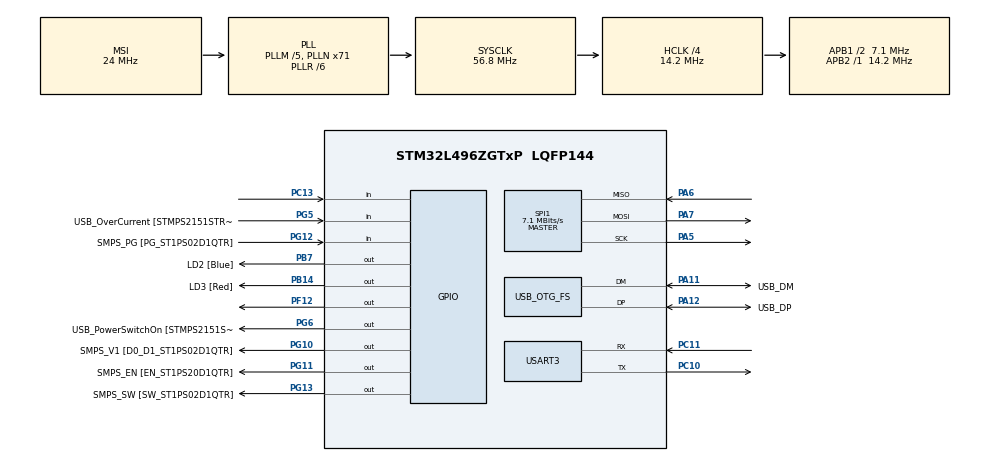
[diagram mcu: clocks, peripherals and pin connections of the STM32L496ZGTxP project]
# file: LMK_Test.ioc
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Mcu.Family=STM32L4
Mcu.Name=STM32L496ZGTxP
Mcu.Package=LQFP144
NVIC.OTG_FS_IRQn=true\:0\:0\:false\:false\:true\:true\:true\:true
NVIC.PriorityGroup=NVIC_PRIORITYGROUP_4
PA10.GPIO_Label=USB_ID
PA10.Signal=USB_OTG_FS_ID
PA11.GPIO_Label=USB_DM
PA11.Mode=Host_Only
PA11.Signal=USB_OTG_FS_DM
PA12.GPIO_Label=USB_DP
PA12.Mode=Host_Only
PA12.Signal=USB_OTG_FS_DP
PA13\ (JTMS/SWDIO).GPIO_Label=TMS
PA13\ (JTMS/SWDIO).Mode=Trace_Asynchronous_SW
PA13\ (JTMS/SWDIO).Signal=SYS_JTMS-SWDIO
PA14\ (JTCK/SWCLK).GPIO_Label=TCK
PA14\ (JTCK/SWCLK).Mode=Trace_Asynchronous_SW
PA14\ (JTCK/SWCLK).Signal=SYS_JTCK-SWCLK
PA5.Mode=Full_Duplex_Master
PA5.Signal=SPI1_SCK
PA6.Mode=Full_Duplex_Master
PA6.Signal=SPI1_MISO
PA7.Mode=Full_Duplex_Master
PA7.Signal=SPI1_MOSI
PA8.GPIO_Label=USB_SOF [TP1]
PA8.Signal=USB_OTG_FS_SOF
PA9.GPIO_Label=USB_VBUS
PA9.Signal=USB_OTG_FS_VBUS
PB14.GPIO_Label=LD3 [Red]
PB14.Signal=GPIO_Output
PB3\ (JTDO/TRACESWO).GPIO_Label=SWO
PB3\ (JTDO/TRACESWO).Mode=Trace_Asynchronous_SW
PB3\ (JTDO/TRACESWO).Signal=SYS_JTDO-SWO
PB7.GPIO_Label=LD2 [Blue]
PB7.Signal=GPIO_Output
PC10.Mode=Asynchronous
PC10.Signal=USART3_TX
PC11.Mode=Asynchronous
PC11.Signal=USART3_RX
PC13.Signal=GPIO_Input
PC14-OSC32_IN\ (PC14).Mode=LSE-External-Oscillator
PC14-OSC32_IN\ (PC14).Signal=RCC_OSC32_IN
PC15-OSC32_OUT\ (PC15).Mode=LSE-External-Oscillator
PC15-OSC32_OUT\ (PC15).Signal=RCC_OSC32_OUT
PF12.Signal=GPIO_Output
PG10.GPIO_Label=SMPS_V1 [D0_D1_ST1PS02D1QTR]
PG10.Signal=GPIO_Output
PG11.GPIO_Label=SMPS_EN [EN_ST1PS20D1QTR]
PG11.Signal=GPIO_Output
PG12.GPIO_Label=SMPS_PG [PG_ST1PS02D1QTR]
PG12.Signal=GPIO_Input
PG13.GPIO_Label=SMPS_SW [SW_ST1PS02D1QTR]
PG13.Signal=GPIO_Output
PG5.GPIO_Label=USB_OverCurrent [STMPS2151STR_FAULT]
PG5.Signal=GPIO_Input
PG6.GPIO_Label=USB_PowerSwitchOn [STMPS2151STR_EN]
PG6.Signal=GPIO_Output
PH0-OSC_IN\ (PH0).GPIO_Label=MCO
PH0-OSC_IN\ (PH0).Signal=RCC_OSC_IN
PH1-OSC_OUT\ (PH1).Signal=RCC_OSC_OUT
ProjectManager.HeapSize=0x200
ProjectManager.StackSize=0x400
ProjectManager.TargetToolchain=STM32CubeIDE
RCC.48MHZClocksFreq_Value=24000000
RCC.ADCFreq_Value=48000000
RCC.AHBCLKDivider=RCC_SYSCLK_DIV4
RCC.AHBFreq_Value=14200000
RCC.APB1CLKDivider=RCC_HCLK_DIV2
RCC.APB1Freq_Value=7100000
RCC.APB1TimFreq_Value=14200000
RCC.APB2Freq_Value=14200000
RCC.APB2TimFreq_Value=14200000
RCC.CortexFreq_Value=14200000
RCC.HCLKFreq_Value=14200000
RCC.HSE_VALUE=8000000
RCC.HSI48_VALUE=48000000
RCC.HSI_VALUE=16000000
RCC.MSIClockRange=RCC_MSIRANGE_9
RCC.MSI_VALUE=24000000
RCC.PLLM=5
RCC.PLLMUL=RCC_PLL_MUL9
RCC.PLLN=71
RCC.PLLR=RCC_PLLR_DIV6
RCC.PLLSAI1N=20
RCC.PRESCALERUSB=RCC_USBCLKSOURCE_PLL_DIV1_5
RCC.SYSCLKFreq_VALUE=56800000
RCC.SYSCLKSource=RCC_SYSCLKSOURCE_PLLCLK
RCC.SYSCLKSourceVirtual=RCC_SYSCLKSOURCE_PLLCLK
RCC.USBFreq_Value=48000000
RCC.VCOOutputFreq_Value=340800000
SPI1.CalculateBaudRate=7.1 MBits/s
SPI1.DataSize=SPI_DATASIZE_8BIT
SPI1.Direction=SPI_DIRECTION_2LINES
SPI1.Mode=SPI_MODE_MASTER
SPI1.NSSPMode=SPI_NSS_PULSE_DISABLE
SPI1.VirtualType=VM_MASTER
USART3.VirtualMode-Asynchronous=VM_ASYNC
USB_HOST.BSP.number=1
USB_HOST.USBH_HandleTypeDef=hUsbHostFS
USB_HOST.VirtualModeFS=Audio
USB_HOST0.BSP.STBoard=false
USB_HOST0.BSP.api=UnknownBspDriver
USB_HOST0.BSP.instance=PG6
USB_HOST0.BSP.ip=GPIO
USB_HOST0.BSP.mode=Output
USB_HOST0.BSP.name=Drive_VBUS_FS
USB_HOST0.BSP.solution=PG6
USB_OTG_FS.VirtualMode=Host_Only
USB_OTG_FS.phy_itface=HCD_PHY_EMBEDDED
VP_USB_HOST_VS_USB_HOST_AUDIO_FS.Mode=AUDIO_FS
board=NUCLEO-L496ZG-P

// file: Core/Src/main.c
/* USER CODE BEGIN Header */
/**
  ******************************************************************************
  * @file           : main.c
  * @brief          : Main program body
  * @Author			: Ronak Sharma
  ******************************************************************************
  * @attention
  * Make sure to See the Baudrate of Slave device, Set the Baudrate accordingly
  *
  * Copyright (c) 2022 STMicroelectronics.
  * All rights reserved.
  *
  * This software is licensed under terms that can be found in the LICENSE file
  * in the root directory of this software component.
  * If no LICENSE file comes with this software, it is provided AS-IS.
  *
  ******************************************************************************
  */
/* USER CODE END Header */
#include "main.h"
#include "usb_host.h"
#include<string.h>
#include<stdio.h>

SPI_HandleTypeDef hspi1;

UART_HandleTypeDef huart3;

/* USER CODE BEGIN PV */
//uint8_t spiData[2];
/* USER CODE END PV */

void SystemClock_Config(void);
static void MX_GPIO_Init(void);
static void MX_SPI1_Init(void);
static void MX_USART3_UART_Init(void);
void MX_USB_HOST_Process(void);

int main(void)
{
  /* USER CODE BEGIN 1 */
	//char uart_buf[50];
	//char spi_buf[20]={0};
	uint8_t Buf[50]={0};
	uint8_t spiData[5]={0};
	/* USER CODE END 1 */

  HAL_Init();
  SystemClock_Config();
  MX_GPIO_Init();
  //MX_LPUART1_UART_Init();
  MX_USB_HOST_Init();
  MX_SPI1_Init();
  MX_USART3_UART_Init();

  //Print something
  strcpy((char*)Buf,"Test\r\n");
  HAL_UART_Transmit(&huart3,Buf,strlen((char*)Buf), 100);

  /*
  //CS pin should default High
  HAL_GPIO_WritePin(GPIOB, GPIO_PIN_7, GPIO_PIN_SET);

  //Enable write enable Latch(allow write operation)
  HAL_GPIO_WritePin(GPIOB, GPIO_PIN_7, GPIO_PIN_RESET);
  HAL_SPI_Transmit(&hspi1, (uint8_t*)&LMK_WREN	,1, 100);
  HAL_GPIO_WritePin(GPIOB, GPIO_PIN_7, GPIO_PIN_RESET);

  //Read Status Register
  HAL_GPIO_WritePin(GPIOB, GPIO_PIN_7, GPIO_PIN_RESET);
  HAL_SPI_Transmit(&hspi1, (uint8_t*)&LMK_RDSR	,1, 100);
  HAL_SPI_Receive(&hspi1, (uint8_t*)spi_buf,1, 100);
  HAL_GPIO_WritePin(GPIOB, GPIO_PIN_7, GPIO_PIN_SET);

  //Printout status register
  sprintf(uart_buf, "Status : 0x%02x \r\n",(unsigned int)spi_buf[0]);
  HAL_UART_Transmit(&huart3, (uint8_t*)uart_buf, strlen(uart_buf), 100);

  //Test bytes to write to LMX
  //E.g
  spi_buf[0]=0xAB;
  spi_buf[1]=0xCD;
  spi_buf[2]=0xEF;

  //Set the starting address
  addr = 0x05;

  //Write 3 bytes starting at given address
  HAL_GPIO_WritePin(GPIOB, GPIO_PIN_7, GPIO_PIN_RESET);
  HAL_SPI_Transmit(&hspi1, (uint8_t*)&LMK_WRITE, 1, 100);
  HAL_SPI_Transmit(&hspi1, (uint8_t*)&addr, 1, 100);
  HAL_SPI_Transmit(&hspi1, (uint8_t*)spi_buf, 3, 100);
  HAL_GPIO_WritePin(GPIOB, GPIO_PIN_7, GPIO_PIN_SET);

  */

  while(1){

  while (! HAL_GPIO_ReadPin(GPIOC, GPIO_PIN_13));
  HAL_Delay(200);

  HAL_GPIO_TogglePin(GPIOB, GPIO_PIN_7);
  strcpy((char*)Buf, "\nApplication is Running\r");
  HAL_UART_Transmit(&huart3, Buf, strlen((char*)Buf), HAL_MAX_DELAY);

  //Make CS Pin High
  HAL_GPIO_WritePin(GPIOF, GPIO_PIN_12, GPIO_PIN_SET);
  HAL_Delay(10);

  //Read data
  //1.Put CS low to Activate(to make connection) the SPI slave device
  HAL_GPIO_WritePin(GPIOF, GPIO_PIN_12, GPIO_PIN_RESET);
  //2. Transmit Register Address
 spiData[0]=0x05; // SPI Register address,
  HAL_SPI_Transmit(&hspi1, spiData, 1, 100); // this will make connection with this addressed Register of SPI slave device

  //3.Read
  HAL_SPI_Receive(&hspi1, spiData, 5, 100);
  //4. bring CS pin high to break the connection with Slave device
  HAL_GPIO_WritePin(GPIOF, GPIO_PIN_12, GPIO_PIN_SET);

  sprintf((char*)Buf,"\nReceived Data is : 0x%X  0x%X  0x%X  0x%X  0x%X",spiData[0],spiData[1],spiData[2],spiData[3],spiData[4]);
  HAL_UART_Transmit(&huart3, Buf, strlen((char*)Buf), HAL_MAX_DELAY);

  sprintf((char*)Buf,"\nReceived Data is : %s",spiData);
   HAL_UART_Transmit(&huart3, Buf, strlen((char*)Buf), HAL_MAX_DELAY);

  HAL_Delay(100);

  }
  /* USER CODE END 3 */
}
void SystemClock_Config(void)
{
  RCC_OscInitTypeDef RCC_OscInitStruct = {0};
  RCC_ClkInitTypeDef RCC_ClkInitStruct = {0};

  /** Configure the main internal regulator output voltage
  */
  if (HAL_PWREx_ControlVoltageScaling(PWR_REGULATOR_VOLTAGE_SCALE1) != HAL_OK)
  {
    Error_Handler();
  }

  /** Configure LSE Drive Capability
  */
  HAL_PWR_EnableBkUpAccess();
  __HAL_RCC_LSEDRIVE_CONFIG(RCC_LSEDRIVE_LOW);

  /** Initializes the RCC Oscillators according to the specified parameters
  * in the RCC_OscInitTypeDef structure.
  */
  RCC_OscInitStruct.OscillatorType = RCC_OSCILLATORTYPE_LSE|RCC_OSCILLATORTYPE_MSI;
  RCC_OscInitStruct.LSEState = RCC_LSE_ON;
  RCC_OscInitStruct.MSIState = RCC_MSI_ON;
  RCC_OscInitStruct.MSICalibrationValue = 0;
  RCC_OscInitStruct.MSIClockRange = RCC_MSIRANGE_9;
  RCC_OscInitStruct.PLL.PLLState = RCC_PLL_ON;
  RCC_OscInitStruct.PLL.PLLSource = RCC_PLLSOURCE_MSI;
  RCC_OscInitStruct.PLL.PLLM = 5;
  RCC_OscInitStruct.PLL.PLLN = 71;
  RCC_OscInitStruct.PLL.PLLP = RCC_PLLP_DIV2;
  RCC_OscInitStruct.PLL.PLLQ = RCC_PLLQ_DIV2;
  RCC_OscInitStruct.PLL.PLLR = RCC_PLLR_DIV6;
  if (HAL_RCC_OscConfig(&RCC_OscInitStruct) != HAL_OK)
  {
    Error_Handler();
  }

  /** Initializes the CPU, AHB and APB buses clocks
  */
  RCC_ClkInitStruct.ClockType = RCC_CLOCKTYPE_HCLK|RCC_CLOCKTYPE_SYSCLK
                              |RCC_CLOCKTYPE_PCLK1|RCC_CLOCKTYPE_PCLK2;
  RCC_ClkInitStruct.SYSCLKSource = RCC_SYSCLKSOURCE_PLLCLK;
  RCC_ClkInitStruct.AHBCLKDivider = RCC_SYSCLK_DIV4;
  RCC_ClkInitStruct.APB1CLKDivider = RCC_HCLK_DIV2;
  RCC_ClkInitStruct.APB2CLKDivider = RCC_HCLK_DIV1;

  if (HAL_RCC_ClockConfig(&RCC_ClkInitStruct, FLASH_LATENCY_0) != HAL_OK)
  {
    Error_Handler();
  }

  /** Enable MSI Auto calibration
  */
  HAL_RCCEx_EnableMSIPLLMode();
}

static void MX_SPI1_Init(void)
{

  /* SPI1 parameter configuration*/
  hspi1.Instance = SPI1;
  hspi1.Init.Mode = SPI_MODE_MASTER;
  hspi1.Init.Direction = SPI_DIRECTION_2LINES;
  hspi1.Init.DataSize = SPI_DATASIZE_8BIT;
  hspi1.Init.CLKPolarity = SPI_POLARITY_LOW;
  hspi1.Init.CLKPhase = SPI_PHASE_1EDGE;
  hspi1.Init.NSS = SPI_NSS_SOFT;
  hspi1.Init.BaudRatePrescaler = SPI_BAUDRATEPRESCALER_2;
  hspi1.Init.FirstBit = SPI_FIRSTBIT_MSB;
  hspi1.Init.TIMode = SPI_TIMODE_DISABLE;
  hspi1.Init.CRCCalculation = SPI_CRCCALCULATION_DISABLE;
  hspi1.Init.CRCPolynomial = 7;
  hspi1.Init.CRCLength = SPI_CRC_LENGTH_DATASIZE;
  hspi1.Init.NSSPMode = SPI_NSS_PULSE_DISABLE;
  if (HAL_SPI_Init(&hspi1) != HAL_OK)
  {
    Error_Handler();
  }

}

static void MX_USART3_UART_Init(void)
{

  huart3.Instance = USART3;
  huart3.Init.BaudRate = 115200;
  huart3.Init.WordLength = UART_WORDLENGTH_8B;
  huart3.Init.StopBits = UART_STOPBITS_1;
  huart3.Init.Parity = UART_PARITY_NONE;
  huart3.Init.Mode = UART_MODE_TX_RX;
  huart3.Init.HwFlowCtl = UART_HWCONTROL_NONE;
  huart3.Init.OverSampling = UART_OVERSAMPLING_16;
  huart3.Init.OneBitSampling = UART_ONE_BIT_SAMPLE_DISABLE;
  huart3.AdvancedInit.AdvFeatureInit = UART_ADVFEATURE_NO_INIT;
  if (HAL_UART_Init(&huart3) != HAL_OK)
  {
    Error_Handler();
  }

}

static void MX_GPIO_Init(void)
{
  GPIO_InitTypeDef GPIO_InitStruct = {0};

  /* GPIO Ports Clock Enable */
  __HAL_RCC_GPIOC_CLK_ENABLE();
  __HAL_RCC_GPIOH_CLK_ENABLE();
  __HAL_RCC_GPIOA_CLK_ENABLE();
  __HAL_RCC_GPIOF_CLK_ENABLE();
  __HAL_RCC_GPIOB_CLK_ENABLE();
  __HAL_RCC_GPIOG_CLK_ENABLE();
  HAL_PWREx_EnableVddIO2();

  /*Configure GPIO pin Output Level */
  HAL_GPIO_WritePin(GPIOF, GPIO_PIN_12, GPIO_PIN_RESET);

  /*Configure GPIO pin Output Level */
  HAL_GPIO_WritePin(GPIOB, LD3_Pin|LD2_Pin, GPIO_PIN_RESET);

  /*Configure GPIO pin Output Level */
  HAL_GPIO_WritePin(GPIOG, USB_PowerSwitchOn_Pin|SMPS_V1_Pin|SMPS_EN_Pin|SMPS_SW_Pin, GPIO_PIN_RESET);

  /*Configure GPIO pin : PC13 */
  GPIO_InitStruct.Pin = GPIO_PIN_13;
  GPIO_InitStruct.Mode = GPIO_MODE_INPUT;
  GPIO_InitStruct.Pull = GPIO_NOPULL;
  HAL_GPIO_Init(GPIOC, &GPIO_InitStruct);

  /*Configure GPIO pin : PF12 */
  GPIO_InitStruct.Pin = GPIO_PIN_12;
  GPIO_InitStruct.Mode = GPIO_MODE_OUTPUT_PP;
  GPIO_InitStruct.Pull = GPIO_NOPULL;
  GPIO_InitStruct.Speed = GPIO_SPEED_FREQ_LOW;
  HAL_GPIO_Init(GPIOF, &GPIO_InitStruct);

  /*Configure GPIO pins : LD3_Pin LD2_Pin */
  GPIO_InitStruct.Pin = LD3_Pin|LD2_Pin;
  GPIO_InitStruct.Mode = GPIO_MODE_OUTPUT_PP;
  GPIO_InitStruct.Pull = GPIO_NOPULL;
  GPIO_InitStruct.Speed = GPIO_SPEED_FREQ_LOW;
  HAL_GPIO_Init(GPIOB, &GPIO_InitStruct);

  /*Configure GPIO pins : USB_OverCurrent_Pin SMPS_PG_Pin */
  GPIO_InitStruct.Pin = USB_OverCurrent_Pin|SMPS_PG_Pin;
  GPIO_InitStruct.Mode = GPIO_MODE_INPUT;
  GPIO_InitStruct.Pull = GPIO_NOPULL;
  HAL_GPIO_Init(GPIOG, &GPIO_InitStruct);

  /*Configure GPIO pins : USB_PowerSwitchOn_Pin SMPS_V1_Pin SMPS_EN_Pin SMPS_SW_Pin */
  GPIO_InitStruct.Pin = USB_PowerSwitchOn_Pin|SMPS_V1_Pin|SMPS_EN_Pin|SMPS_SW_Pin;
  GPIO_InitStruct.Mode = GPIO_MODE_OUTPUT_PP;
  GPIO_InitStruct.Pull = GPIO_NOPULL;
  GPIO_InitStruct.Speed = GPIO_SPEED_FREQ_LOW;
  HAL_GPIO_Init(GPIOG, &GPIO_InitStruct);

}

void Error_Handler(void)
{
  __disable_irq();
  while (1)
  {
  }
}
